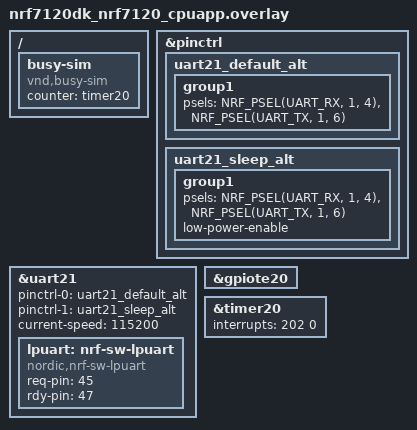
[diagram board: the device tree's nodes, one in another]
/* Required loopbacks:
 * P1.04 <-> P1.06
 * P1.13 <-> P1.15
 */

&pinctrl {
	uart21_default_alt: uart21_default_alt {
		group1 {
			psels = <NRF_PSEL(UART_RX, 1, 4)>,
				<NRF_PSEL(UART_TX, 1, 6)>;
		};
	};

	uart21_sleep_alt: uart21_sleep_alt {
		group1 {
			psels = <NRF_PSEL(UART_RX, 1, 4)>,
				<NRF_PSEL(UART_TX, 1, 6)>;
			low-power-enable;
		};
	};
};

&uart21 {
	status = "okay";
	pinctrl-0 = <&uart21_default_alt>;
	pinctrl-1 = <&uart21_sleep_alt>;
	pinctrl-names = "default", "sleep";
	current-speed = <115200>;

	lpuart: nrf-sw-lpuart {
		compatible = "nordic,nrf-sw-lpuart";
		status = "okay";
		req-pin = <45>;
		rdy-pin = <47>;
	};
};

&gpiote20 {
	status = "okay";
};

&timer20 {
	status = "okay";
	interrupts = <202 0>;
};

/ {
	busy-sim {
		compatible = "vnd,busy-sim";
		status = "okay";
		counter = <&timer20>;
	};
};
